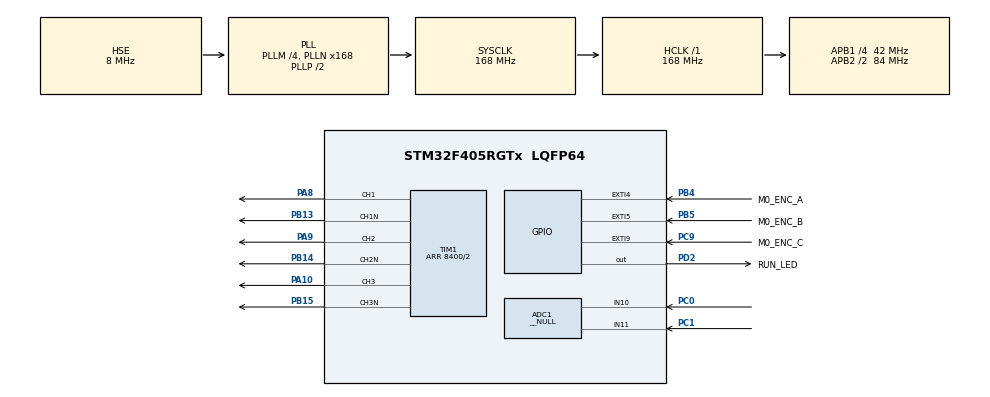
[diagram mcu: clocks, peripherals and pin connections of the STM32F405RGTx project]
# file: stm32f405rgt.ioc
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ADC1.Channel-0\#ChannelRegularConversion=ADC_CHANNEL_TEMPSENSOR
ADC1.Channel-1\#ChannelInjectedConversion=ADC_CHANNEL_10
ADC1.Channel-2\#ChannelInjectedConversion=ADC_CHANNEL_11
ADC1.ContinuousConvMode=DISABLE
ADC1.DMAContinuousRequests=DISABLE
ADC1.EOCSelection=ADC_EOC_SINGLE_CONV
ADC1.ExternalTrigInjecConv=ADC_EXTERNALTRIGINJECCONV_T1_TRGO
ADC1.InjNumberOfConversion=2
ADC1.InjectedConvMode=None
ADC1.InjectedOffset-1\#ChannelInjectedConversion=0
ADC1.InjectedOffset-2\#ChannelInjectedConversion=0
ADC1.InjectedRank-1\#ChannelInjectedConversion=1
ADC1.InjectedRank-2\#ChannelInjectedConversion=2
ADC1.Mode=__NULL
ADC1.NbrOfConversion=1
ADC1.NbrOfConversionFlag=1
ADC1.Rank-0\#ChannelRegularConversion=1
ADC1.SamplingTime-0\#ChannelRegularConversion=ADC_SAMPLETIME_15CYCLES
ADC1.SamplingTime-1\#ChannelInjectedConversion=ADC_SAMPLETIME_15CYCLES
ADC1.SamplingTime-2\#ChannelInjectedConversion=ADC_SAMPLETIME_15CYCLES
ADC1.master=1
Mcu.Family=STM32F4
Mcu.Name=STM32F405RGTx
Mcu.Package=LQFP64
NVIC.ADC_IRQn=true\:0\:0\:true\:false\:true\:true\:true\:true
NVIC.EXTI4_IRQn=true\:0\:0\:true\:false\:true\:true\:true\:true
NVIC.EXTI9_5_IRQn=true\:0\:0\:true\:false\:true\:true\:true\:true
NVIC.PriorityGroup=NVIC_PRIORITYGROUP_4
NVIC.TIM4_IRQn=true\:0\:0\:true\:false\:true\:true\:true\:true
PA10.GPIO_Speed=GPIO_SPEED_FREQ_HIGH
PA10.Signal=S_TIM1_CH3
PA13.Mode=Serial_Wire
PA13.Signal=SYS_JTMS-SWDIO
PA14.Mode=Serial_Wire
PA14.Signal=SYS_JTCK-SWCLK
PA8.GPIO_Speed=GPIO_SPEED_FREQ_HIGH
PA8.Signal=S_TIM1_CH1
PA9.GPIO_Speed=GPIO_SPEED_FREQ_HIGH
PA9.Signal=S_TIM1_CH2
PB13.GPIO_Speed=GPIO_SPEED_FREQ_HIGH
PB13.Mode=PWM Generation1 CH1 CH1N
PB13.Signal=TIM1_CH1N
PB14.GPIO_Speed=GPIO_SPEED_FREQ_HIGH
PB14.Mode=PWM Generation2 CH2 CH2N
PB14.Signal=TIM1_CH2N
PB15.GPIO_Speed=GPIO_SPEED_FREQ_HIGH
PB15.Mode=PWM Generation3 CH3 CH3N
PB15.Signal=TIM1_CH3N
PB4.GPIO_Label=M0_ENC_A
PB4.GPIO_ModeDefaultEXTI=GPIO_MODE_IT_RISING_FALLING
PB4.Signal=GPXTI4
PB5.GPIO_Label=M0_ENC_B
PB5.GPIO_ModeDefaultEXTI=GPIO_MODE_IT_RISING_FALLING
PB5.Signal=GPXTI5
PC0.Signal=ADCx_IN10
PC1.Signal=ADCx_IN11
PC9.GPIO_Label=M0_ENC_C
PC9.GPIO_ModeDefaultEXTI=GPIO_MODE_IT_RISING_FALLING
PC9.Signal=GPXTI9
PD2.GPIO_Label=RUN_LED
PD2.GPIO_PuPd=GPIO_PULLDOWN
PD2.GPIO_Speed=GPIO_SPEED_FREQ_MEDIUM
PD2.Signal=GPIO_Output
PH0-OSC_IN.Mode=HSE-External-Oscillator
PH0-OSC_IN.Signal=RCC_OSC_IN
PH1-OSC_OUT.Mode=HSE-External-Oscillator
PH1-OSC_OUT.Signal=RCC_OSC_OUT
ProjectManager.HeapSize=0x200
ProjectManager.StackSize=0x1000
ProjectManager.TargetToolchain=MDK-ARM V5.32
RCC.48MHZClocksFreq_Value=84000000
RCC.AHBFreq_Value=168000000
RCC.APB1CLKDivider=RCC_HCLK_DIV4
RCC.APB1Freq_Value=42000000
RCC.APB1TimFreq_Value=84000000
RCC.APB2CLKDivider=RCC_HCLK_DIV2
RCC.APB2Freq_Value=84000000
RCC.APB2TimFreq_Value=168000000
RCC.CortexFreq_Value=168000000
RCC.HCLKFreq_Value=168000000
RCC.HSE_VALUE=8000000
RCC.HSI_VALUE=16000000
RCC.LSE_VALUE=32768
RCC.PLLM=4
RCC.PLLN=168
RCC.PLLSourceVirtual=RCC_PLLSOURCE_HSE
RCC.SYSCLKFreq_VALUE=168000000
RCC.SYSCLKSource=RCC_SYSCLKSOURCE_PLLCLK
RCC.VCOOutputFreq_Value=336000000
SH.ADCx_IN10.0=ADC1_IN10,IN10
SH.ADCx_IN11.0=ADC1_IN11,IN11
SH.S_TIM1_CH1.0=TIM1_CH1,PWM Generation1 CH1 CH1N
SH.S_TIM1_CH2.0=TIM1_CH2,PWM Generation2 CH2 CH2N
SH.S_TIM1_CH3.0=TIM1_CH3,PWM Generation3 CH3 CH3N
TIM1.AutoReloadPreload=TIM_AUTORELOAD_PRELOAD_ENABLE
TIM1.Channel-PWM\ Generation1\ CH1\ CH1N=TIM_CHANNEL_1
TIM1.Channel-PWM\ Generation2\ CH2\ CH2N=TIM_CHANNEL_2
TIM1.Channel-PWM\ Generation3\ CH3\ CH3N=TIM_CHANNEL_3
TIM1.CounterMode=TIM_COUNTERMODE_CENTERALIGNED1
TIM1.DeadTime=100
TIM1.OCMode_PWM-PWM\ Generation1\ CH1\ CH1N=TIM_OCMODE_PWM2
TIM1.OCMode_PWM-PWM\ Generation2\ CH2\ CH2N=TIM_OCMODE_PWM2
TIM1.OCMode_PWM-PWM\ Generation3\ CH3\ CH3N=TIM_OCMODE_PWM2
TIM1.Period=8400/2
TIM1.Pulse-PWM\ Generation1\ CH1\ CH1N=4200
TIM1.Pulse-PWM\ Generation2\ CH2\ CH2N=4200
TIM1.Pulse-PWM\ Generation3\ CH3\ CH3N=4200
TIM1.RepetitionCounter=1
TIM1.TIM_MasterOutputTrigger=TIM_TRGO_UPDATE
TIM4.AutoReloadPreload=TIM_AUTORELOAD_PRELOAD_ENABLE
TIM4.Period=500-1
TIM4.Prescaler=84 - 1
VP_ADC1_TempSens_Input.Mode=IN-TempSens
VP_TIM1_VS_ClockSourceINT.Mode=Internal
VP_TIM4_VS_ClockSourceINT.Mode=Internal
board=custom

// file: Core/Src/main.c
/* USER CODE BEGIN Header */
/**
  ******************************************************************************
  * @file           : main.c
  * @brief          : Main program body
  ******************************************************************************
  * @attention
  *
  * Copyright (c) 2025 STMicroelectronics.
  * All rights reserved.
  *
  * This software is licensed under terms that can be found in the LICENSE file
  * in the root directory of this software component.
  * If no LICENSE file comes with this software, it is provided AS-IS.
  *
  ******************************************************************************
  */
/* USER CODE END Header */
#include "main.h"
#include "adc.h"
#include "tim.h"
#include "gpio.h"

/* USER CODE BEGIN Includes */
#include "user_main.h"
/* USER CODE END Includes */

void SystemClock_Config(void);

/* USER CODE BEGIN 0 */
/**
 * @brief RTT通道0打印浮点�?
 *
 * @param value
 */
void SEGGER_Printf_Float(float value){
    char buffer[50] = {0,};
    sprintf(buffer, "%.4f\n", value);   // 格式化为字符�?
    SEGGER_RTT_printf(0, "%s", buffer); // 打印字符�?
}
/* USER CODE END 0 */

int main(void)
{

  /* MCU Configuration--------------------------------------------------------*/

  /* Reset of all peripherals, Initializes the Flash interface and the Systick. */
  HAL_Init();

  /* Configure the system clock */
  SystemClock_Config();

  /* Initialize all configured peripherals */
  MX_GPIO_Init();
  MX_TIM1_Init();
  MX_TIM4_Init();
  MX_ADC1_Init();
  /* USER CODE BEGIN 2 */
  SEGGER_RTT_SetTerminal(0); //! 设置终端0
  DWT_Timer_Init(); // 初始化DWT定时
  main_Cpp();       // 跳转C++环境
  /* USER CODE END 2 */

  /* Infinite loop */
  while (1)
  {

  }
}

void SystemClock_Config(void)
{
  RCC_OscInitTypeDef RCC_OscInitStruct = {0};
  RCC_ClkInitTypeDef RCC_ClkInitStruct = {0};

  /** Configure the main internal regulator output voltage
  */
  __HAL_RCC_PWR_CLK_ENABLE();
  __HAL_PWR_VOLTAGESCALING_CONFIG(PWR_REGULATOR_VOLTAGE_SCALE1);

  /** Initializes the RCC Oscillators according to the specified parameters
  * in the RCC_OscInitTypeDef structure.
  */
  RCC_OscInitStruct.OscillatorType = RCC_OSCILLATORTYPE_HSE;
  RCC_OscInitStruct.HSEState = RCC_HSE_ON;
  RCC_OscInitStruct.PLL.PLLState = RCC_PLL_ON;
  RCC_OscInitStruct.PLL.PLLSource = RCC_PLLSOURCE_HSE;
  RCC_OscInitStruct.PLL.PLLM = 4;
  RCC_OscInitStruct.PLL.PLLN = 168;
  RCC_OscInitStruct.PLL.PLLP = RCC_PLLP_DIV2;
  RCC_OscInitStruct.PLL.PLLQ = 4;
  if (HAL_RCC_OscConfig(&RCC_OscInitStruct) != HAL_OK)
  {
    Error_Handler();
  }

  /** Initializes the CPU, AHB and APB buses clocks
  */
  RCC_ClkInitStruct.ClockType = RCC_CLOCKTYPE_HCLK|RCC_CLOCKTYPE_SYSCLK
                              |RCC_CLOCKTYPE_PCLK1|RCC_CLOCKTYPE_PCLK2;
  RCC_ClkInitStruct.SYSCLKSource = RCC_SYSCLKSOURCE_PLLCLK;
  RCC_ClkInitStruct.AHBCLKDivider = RCC_SYSCLK_DIV1;
  RCC_ClkInitStruct.APB1CLKDivider = RCC_HCLK_DIV4;
  RCC_ClkInitStruct.APB2CLKDivider = RCC_HCLK_DIV2;

  if (HAL_RCC_ClockConfig(&RCC_ClkInitStruct, FLASH_LATENCY_5) != HAL_OK)
  {
    Error_Handler();
  }
}

void Error_Handler(void)
{
  __disable_irq();
  while (1)
  {
  }
}
